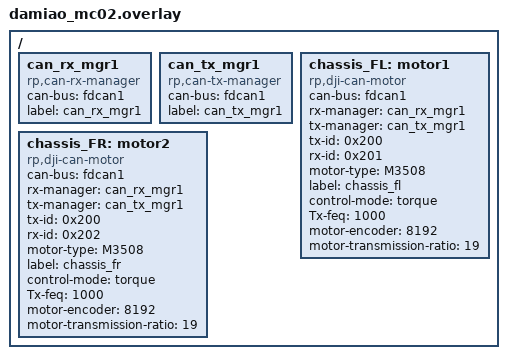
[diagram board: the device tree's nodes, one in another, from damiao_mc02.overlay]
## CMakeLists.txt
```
cmake_minimum_required(VERSION 3.20)

set(BOARD damiao_mc02)
find_package(Zephyr REQUIRED HINTS $ENV{ZEPHYR_BASE})
project(ws2812)

target_sources(app PRIVATE src/main.cpp)
# Include local can_tx_manager driver implementation from manifest drivers
zephyr_library_sources(../../../../drivers/can_tx_manager/can_tx_manager.c)
```

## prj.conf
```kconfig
CONFIG_LED_STRIP=y
CONFIG_CAN=y
CONFIG_CPP=y
CONFIG_CAN_RX_MANAGER=y
CONFIG_CAN_TX_MANAGER=y
CONFIG_MOTOR=y
CONFIG_ASSERT=y
CONFIG_CAN_LOOPBACK=y
# CONFIG_CAN_PREEMPTIVE_CONFIG=y

# DJI 电机 CAN 通常为 1Mbps；
CONFIG_CAN_DEFAULT_BITRATE=1000000

# # msgq 满导致丢帧监控
# CONFIG_CAN_RX_MANAGER_MSGQ_MONITOR=y
# CONFIG_CAN_RX_MANAGER_MSGQ_WARN_EVERY_N_DROPS=1

# DJI 心跳自动检测（shared system workqueue）
CONFIG_MOTOR_DJI_HEARTBEAT_AUTOCHECK=y
CONFIG_MOTOR_DJI_HEARTBEAT_POLL_PERIOD_MS=100



# RTT (Real-Time Transfer) Configuration
CONFIG_USE_SEGGER_RTT=y
CONFIG_CONSOLE=y
CONFIG_RTT_CONSOLE=y
CONFIG_UART_CONSOLE=n

# Optional: Enable RTT logging backend
CONFIG_LOG_BACKEND_RTT=y
CONFIG_LOG_BACKEND_UART=n

CONFIG_LOG=y

# Enable floating-point formatting for Zephyr's cbprintf (used by logging/printf).
# Note: enabling this increases firmware size.
CONFIG_FPU=y
CONFIG_NEWLIB_LIBC=y
```

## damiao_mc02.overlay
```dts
/*dts-test-motor*/
/ {
    can_rx_mgr1: can_rx_mgr1 {
        compatible = "rp,can-rx-manager";
        status = "okay";
        can-bus = <&fdcan1>;
        label = "can_rx_mgr1";
    };

    can_tx_mgr1: can_tx_mgr1 {
        compatible = "rp,can-tx-manager";
        status = "okay";
        can-bus = <&fdcan1>;
        label = "can_tx_mgr1";
    };

    chassis_FL:motor1{
        compatible = "rp,dji-can-motor";
        status = "okay";
        can-bus = <&fdcan1>;
        rx-manager = <&can_rx_mgr1>;
        tx-manager = <&can_tx_mgr1>;
        tx-id = <0x200>;
        rx-id = <0x201>;
        motor-type = "M3508";
        label = "chassis_fl";
        control-mode = "torque";
        Tx-feq = <1000>;
        motor-encoder = <8192>;
        motor-transmission-ratio = <19>;
    };

    chassis_FR:motor2{
        compatible = "rp,dji-can-motor";
        status = "okay";
        can-bus = <&fdcan1>;
        rx-manager = <&can_rx_mgr1>;
        tx-manager = <&can_tx_mgr1>;
        tx-id = <0x200>;
        rx-id = <0x202>;
        motor-type = "M3508";
        label = "chassis_fr";
        control-mode = "torque";
        Tx-feq = <1000>;
        motor-encoder = <8192>;
        motor-transmission-ratio = <19>;
    };



};
```

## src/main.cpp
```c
#include <zephyr/kernel.h>
#include <zephyr/device.h>
#include <zephyr/devicetree.h>
#include <zephyr/logging/log.h>
#include <zephyr/sys/printk.h>

#include <drivers/motor.h>
#include <drivers/can_tx_manager.h>
#include <drivers/can_rx_manager.h>
#include <string.h>
#include <math.h>

LOG_MODULE_REGISTER(app, LOG_LEVEL_INF);

#define MOTOR_3508_CURRENT_MAX 10000
#define MOTOR_2006_CURRENT_MAX 8000

#define CHASSIS_FL_NODE DT_NODELABEL(chassis_fl)
#define CHASSIS_FR_NODE DT_NODELABEL(chassis_fr)
#define RX_MANAGER_NODE DT_NODELABEL(can_rx_mgr1)

static float angle_rad = 0.0f;        // 正弦函数的角度（弧度）
static const float ANGLE_STEP = 0.1f; // 每次调用的角度步长（控制正弦频率）
#define M_PI 3.14159265358979323846   /* pi */

int main(void)
{
    LOG_INF("[app] start");
    const struct device *motor_fl = DEVICE_DT_GET(CHASSIS_FL_NODE);
    const struct device *motor_fr = DEVICE_DT_GET(CHASSIS_FR_NODE);
    const struct device *rx_mgr   = DEVICE_DT_GET(RX_MANAGER_NODE);
    const char *motor_type = DT_PROP(CHASSIS_FL_NODE, motor_type);
    if (!motor_fl) {
        LOG_ERR("motor FL not found");
        return -ENODEV;
    }
    if (!motor_fr) {
        LOG_ERR("motor FR not found");
        return -ENODEV;
    }

    if (!device_is_ready(motor_fl)) {
        LOG_ERR("motor FL not ready: %s", motor_fl->name);
        return -ENODEV;
    }
    if (!device_is_ready(motor_fr)) {
        LOG_ERR("motor FR not ready: %s", motor_fr->name);
        return -ENODEV;
    }

    if(!rx_mgr) {
        LOG_ERR("CAN RX manager not found");
        return -ENODEV;
    }
    if(!device_is_ready(rx_mgr)) {
        LOG_ERR("CAN RX manager not ready: %s", rx_mgr->name);
        return -ENODEV;
    }

    int current_max = 0;

    if(strcmp(motor_type, "M3508") == 0)
    {
        current_max = MOTOR_3508_CURRENT_MAX;
    }
    else if(strcmp(motor_type, "M2006") == 0)
    {
        current_max = MOTOR_2006_CURRENT_MAX;
    }
    else
    {
        LOG_WRN("Unknown motor type '%s', using default current max", motor_type);
        current_max = 1000;
    }


    register_motor(motor_fl);
    register_motor(motor_fr);

    while (true) {
        float sin_val = sin(angle_rad);
        float current_float = current_max * 0.15f * sin_val;
        int current = (int)round(current_float);

        // 更新角度（循环0~2π，实现正弦波循环）
        angle_rad += ANGLE_STEP;
        if (angle_rad >= 2 * M_PI)
        {
            angle_rad = 0.0f;
        }

        const sMotor_Receive_Data_t *fl = get_motor_rxdata(motor_fl);
        const sMotor_Receive_Data_t *fr = get_motor_rxdata(motor_fr);

        // 接收函数检查
        LOG_INF("FL angle=%d speed=%d current=%d alive=%d temp=%d",
                    (int)fl->angle, (int)fl->speed, (int)fl->current,
                    get_motor_heartbeat_status(motor_fl) ? 1 : 0, (int)fl->specific_data.m3508.temp);
        LOG_INF("FR angle=%d speed=%d current=%d alive=%d temp=%d",
                (int)fr->angle, (int)fr->speed, (int)fr->current,
                get_motor_heartbeat_status(motor_fr) ? 1 : 0, (int)fr->specific_data.m3508.temp);

        // 发送函数检查
        motor_update_serialized(motor_fl, current);
        motor_update_serialized(motor_fr, current);
        // can_tx_manager_send(can_tx_mgr, K_FOREVER, NULL,
        //                     0x200, NULL);
        LOG_INF("CAN RX load: %.2f%%", (double)can_rx_manager_calculate_load(rx_mgr, 1000000, 0));
        k_sleep(K_MSEC(100));
    }

    return 0;
}
```
